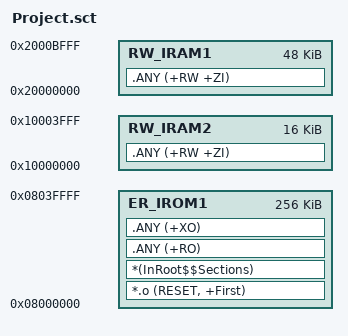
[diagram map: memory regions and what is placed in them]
; ******************************************************************
; *** Scatter-Loading Description File generated by Embedded IDE ***
; ******************************************************************

LR_IROM1 0x08000000 0x00040000 {
	ER_IROM1 0x08000000 0x00040000 {
		*.o (RESET, +First) 
		*(InRoot$$Sections) 
		.ANY (+RO) 
		.ANY (+XO) 
	}
	RW_IRAM1 0x20000000 0x0000c000 {
		.ANY (+RW +ZI) 
	}
	RW_IRAM2 0x10000000 0x00004000 {
		.ANY (+RW +ZI) 
	}
}

